# FM33FG0XXA register map
File version: 1.0
CPU: SC000 r1p0, little endian, MPU, no FPU, 3 interrupt priority bits
Registers are 32-bit, read-only, reset 0x0 unless marked. A register's access mark holds for its fields unless they carry their own. Offsets are from the block's base; [hi:lo] are bit positions.

## UART — UART module information
Base 0x40017C00
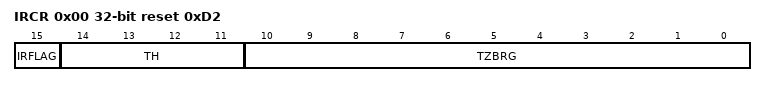
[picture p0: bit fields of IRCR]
0x00 IRCR rw reset 0xD2 — Infrared modulation Control Register
  [15] IRFLAG — IRFLAG field description
  [14:11] TH — TH field description
  [10:0] TZBRG — TZBRG field description

## USART4 — USART4 module information
Base 0x40011C00
Same registers: USART5 0x40012000
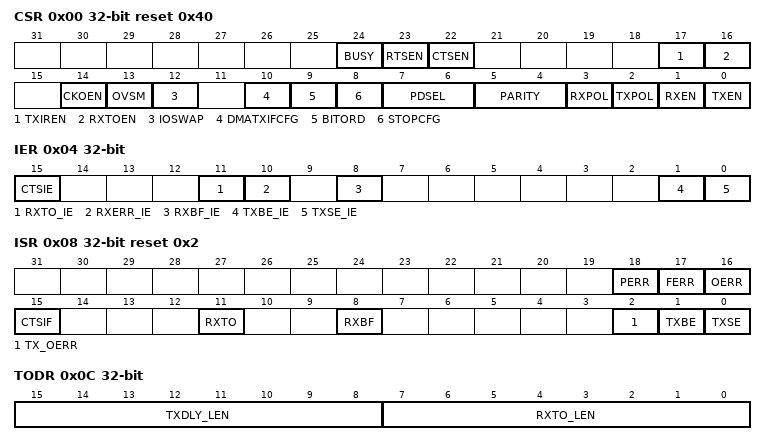
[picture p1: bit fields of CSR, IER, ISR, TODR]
0x00 CSR access per field reset 0x40 — USART Control Status Register
  [24] BUSY ro — BUSY field description
  [23] RTSEN rw — RTSEN field description
  [22] CTSEN rw — CTSEN field description
  [17] TXIREN rw — TXIREN field description
  [16] RXTOEN rw — RXTOEN field description
  [14] CKOEN rw — CKOEN field description
  [13] OVSM rw — OVSM field description
  [12] IOSWAP rw — IOSWAP field description
  [10] DMATXIFCFG rw — DMATXIFCFG field description
  [9] BITORD rw — BITORD field description
  [8] STOPCFG rw — STOPCFG field description
  [7:6] PDSEL rw — PDSEL field description
  [5:4] PARITY rw — PARITY field description
  [3] RXPOL rw — RXPOL field description
  [2] TXPOL rw — TXPOL field description
  [1] RXEN rw — RXEN field description
  [0] TXEN rw — TXEN field description
0x04 IER rw — USART Interrupt Enable Register
  [15] CTSIE — CTSIE field description
  [11] RXTO_IE — RXTO_IE field description
  [10] RXERR_IE — RXERR_IE field description
  [8] RXBF_IE — RXBF_IE field description
  [1] TXBE_IE — TXBE_IE field description
  [0] TXSE_IE — TXSE_IE field description
0x08 ISR access per field reset 0x2 — USART Interrupt Status Register
  [18] PERR rw — PERR field description
  [17] FERR rw — FERR field description
  [16] OERR rw — OERR field description
  [15] CTSIF rw — CTSIF field description
  [11] RXTO rw — RXTO field description
  [8] RXBF rw — RXBF field description
  [2] TX_OERR rw — TX_OERR field description
  [1] TXBE ro — TXBE field description
  [0] TXSE rw — TXSE field description
0x0C TODR rw — UART Time-Out and Delay Register
  [15:8] TXDLY_LEN — TXDLY_LEN field description
  [7:0] RXTO_LEN — RXTO_LEN field description
0x10 RXBUF — USART Receive Buffer
  [8:0] RXBUF — RXBUF field description
0x14 TXBUF wo — USART Transmit Buffer
  [8:0] TXBUF — TXBUF field description
0x18 BGR rw reset 0x341 — USART Baud rate Generator Register
  [15:0] SPBRG — SPBRG field description
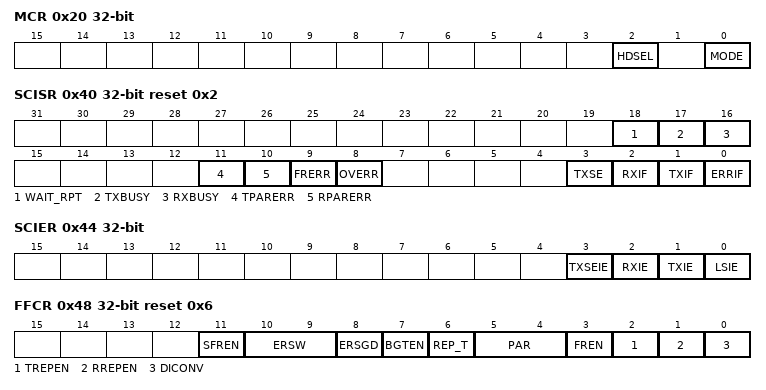
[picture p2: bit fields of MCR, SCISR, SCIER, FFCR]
0x20 MCR rw — USART Mode Control Register
  [2] HDSEL — HDSEL field description
  [0] MODE — MODE field description
0x40 SCISR access per field reset 0x2 — USART Smart Card Interrupt Status Register
  [18] WAIT_RPT ro — WAIT_RPT field description
  [17] TXBUSY ro — TXBUSY field description
  [16] RXBUSY ro — RXBUSY field description
  [11] TPARERR rw — TPARERR field description
  [10] RPARERR rw — RPARERR field description
  [9] FRERR rw — FRERR field description
  [8] OVERR rw — OVERR field description
  [3] TXSE rw — TXSE field description
  [2] RXIF rw — RXIF field description
  [1] TXIF rw — TXIF field description
  [0] ERRIF rw — ERRIF field description
0x44 SCIER rw — USART Smart Card Interrupt Enable Register
  [3] TXSEIE — TXSEIE field description
  [2] RXIE — RXIE field description
  [1] TXIE — TXIE field description
  [0] LSIE — LSIE field description
0x48 FFCR rw reset 0x6 — USART Smart Card Frame Format Control Register
  [11] SFREN — SFREN field description
  [10:9] ERSW — ERSW field description
  [8] ERSGD — ERSGD field description
  [7] BGTEN — BGTEN field description
  [6] REP_T — REP_T field description
  [5:4] PAR — PAR field description
  [3] FREN — FREN field description
  [2] TREPEN — TREPEN field description
  [1] RREPEN — RREPEN field description
  [0] DICONV — DICONV field description
0x4C EGTR rw — USART Smart Card Extra Guard Time Register
  [7:0] TXEGT — TXEGT field description
0x50 CODR rw reset 0x3 — USART Smart Card Clock Output Register
  [4:0] CLKDIV — CLKDIV field description
